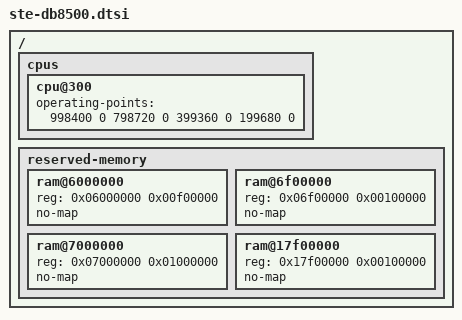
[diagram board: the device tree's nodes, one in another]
#include "ste-dbx5x0.dtsi"
/ {
	cpus {
		cpu@300 {
			operating-points = <998400 0
					    798720 0
					    399360 0
					    199680 0>;
		};
	};
	reserved-memory {
		#address-cells = <1>;
		#size-cells = <1>;
		ranges;
		ram@6000000 {
			reg = <0x06000000 0x00f00000>;
			no-map;
		};
		ram@6f00000 {
			reg = <0x06f00000 0x00100000>;
			no-map;
		};
		ram@7000000 {
			reg = <0x07000000 0x01000000>;
			no-map;
		};
		ram@17f00000 {
			reg = <0x17f00000 0x00100000>;
			no-map;
		};
	};
};
